AUTOSAR XML (schema 00046)
package /ComponentTypes
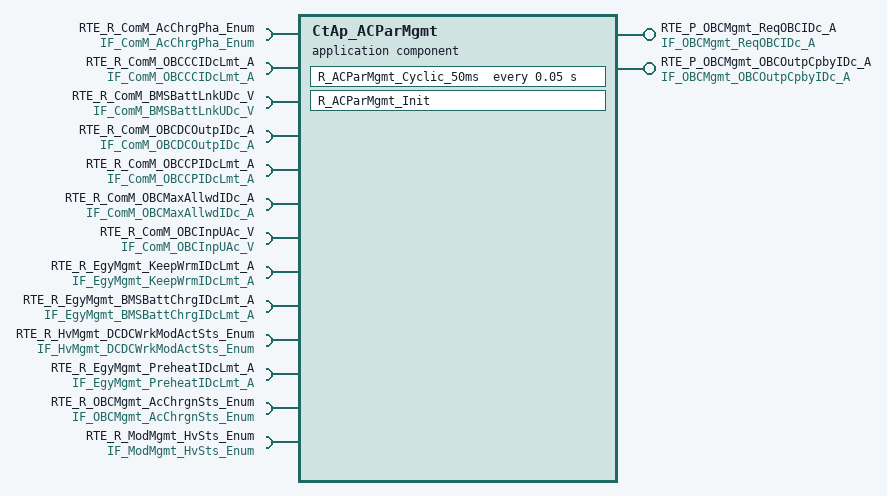
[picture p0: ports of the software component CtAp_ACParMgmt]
  application sw component type CtAp_ACParMgmt
    provide port RTE_P_OBCMgmt_ReqOBCIDc_A: nonqueued-sender-com-spec{data-element=tec_OBCMgmt_ReqOBCIDc_A, init-value=0}, provided-interface=IF_OBCMgmt_ReqOBCIDc_A
    provide port RTE_P_OBCMgmt_OBCOutpCpbyIDc_A: nonqueued-sender-com-spec{data-element=tec_OBCMgmt_OBCOutpCpbyIDc_A, init-value=0}, provided-interface=IF_OBCMgmt_OBCOutpCpbyIDc_A
    13 x require port:
      RTE_R_ComM_AcChrgPha_Enum: nonqueued-receiver-com-spec{data-element=tec_ComM_AcChrgPha_Enum, filter=data-filter-type=ALWAYS, init-value=0}, required-interface=IF_ComM_AcChrgPha_Enum
      RTE_R_ComM_OBCCCIDcLmt_A: nonqueued-receiver-com-spec{data-element=tec_ComM_OBCCCIDcLmt_A, filter=data-filter-type=ALWAYS, init-value=0}, required-interface=IF_ComM_OBCCCIDcLmt_A
      RTE_R_ComM_BMSBattLnkUDc_V: nonqueued-receiver-com-spec{data-element=tec_ComM_BMSBattLnkUDc_V, filter=data-filter-type=ALWAYS, init-value=0}, required-interface=IF_ComM_BMSBattLnkUDc_V
      RTE_R_ComM_OBCDCOutpIDc_A: nonqueued-receiver-com-spec{data-element=tec_ComM_OBCDCOutpIDc_A, filter=data-filter-type=ALWAYS, init-value=0}, required-interface=IF_ComM_OBCDCOutpIDc_A
      RTE_R_ComM_OBCCPIDcLmt_A: nonqueued-receiver-com-spec{data-element=tec_ComM_OBCCPIDcLmt_A, filter=data-filter-type=ALWAYS, init-value=0}, required-interface=IF_ComM_OBCCPIDcLmt_A
      RTE_R_ComM_OBCMaxAllwdIDc_A: nonqueued-receiver-com-spec{data-element=tec_ComM_OBCMaxAllwdIDc_A, filter=data-filter-type=ALWAYS, init-value=0}, required-interface=IF_ComM_OBCMaxAllwdIDc_A
      RTE_R_ComM_OBCInpUAc_V: nonqueued-receiver-com-spec{data-element=tec_ComM_OBCInpUAc_V, filter=data-filter-type=ALWAYS, init-value=0}, required-interface=IF_ComM_OBCInpUAc_V
      RTE_R_EgyMgmt_KeepWrmIDcLmt_A: nonqueued-receiver-com-spec{data-element=tec_EgyMgmt_KeepWrmIDcLmt_A, filter=data-filter-type=ALWAYS, init-value=0}, required-interface=IF_EgyMgmt_KeepWrmIDcLmt_A
      RTE_R_EgyMgmt_BMSBattChrgIDcLmt_A: nonqueued-receiver-com-spec{data-element=tec_EgyMgmt_BMSBattChrgIDcLmt_A, filter=data-filter-type=ALWAYS, init-value=0}, required-interface=IF_EgyMgmt_BMSBattChrgIDcLmt_A
      RTE_R_HvMgmt_DCDCWrkModActSts_Enum: nonqueued-receiver-com-spec{data-element=tec_HvMgmt_DCDCWrkModActSts_Enum, filter=data-filter-type=ALWAYS, init-value=0}, required-interface=IF_HvMgmt_DCDCWrkModActSts_Enum
      RTE_R_EgyMgmt_PreheatIDcLmt_A: nonqueued-receiver-com-spec{data-element=tec_EgyMgmt_PreheatIDcLmt_A, filter=data-filter-type=ALWAYS, init-value=0}, required-interface=IF_EgyMgmt_PreheatIDcLmt_A
      RTE_R_OBCMgmt_AcChrgnSts_Enum: nonqueued-receiver-com-spec{data-element=tec_OBCMgmt_AcChrgnSts_Enum, filter=data-filter-type=ALWAYS, init-value=0}, required-interface=IF_OBCMgmt_AcChrgnSts_Enum
      RTE_R_ModMgmt_HvSts_Enum: nonqueued-receiver-com-spec{data-element=tec_ModMgmt_HvSts_Enum, filter=data-filter-type=ALWAYS, init-value=0}, required-interface=IF_ModMgmt_HvSts_Enum
    behavior CtAp_ACParMgmt_InternalBehavior
      timing event TMT_R_ACParMgmt_Cyclic_50ms: start-on-event=R_ACParMgmt_Cyclic_50ms, period=0.05
      init event CtAp_ACParMgmt_InitEvent: start-on-event=R_ACParMgmt_Init
      runnable R_ACParMgmt_Cyclic_50ms
        data-receive-point-by-arguments:
          13 x access:
            REC_RTE_R_ComM_AcChrgPha_Enum_tec_ComM_AcChrgPha_Enum: accessed-variable=RTE_R_ComM_AcChrgPha_Enum.tec_ComM_AcChrgPha_Enum
            REC_RTE_R_ComM_BMSBattLnkUDc_V_tec_ComM_BMSBattLnkUDc_V: accessed-variable=RTE_R_ComM_BMSBattLnkUDc_V.tec_ComM_BMSBattLnkUDc_V
            REC_RTE_R_ComM_OBCCCIDcLmt_A_tec_ComM_OBCCCIDcLmt_A: accessed-variable=RTE_R_ComM_OBCCCIDcLmt_A.tec_ComM_OBCCCIDcLmt_A
            REC_RTE_R_ComM_OBCCPIDcLmt_A_tec_ComM_OBCCPIDcLmt_A: accessed-variable=RTE_R_ComM_OBCCPIDcLmt_A.tec_ComM_OBCCPIDcLmt_A
            REC_RTE_R_ComM_OBCDCOutpIDc_A_tec_ComM_OBCDCOutpIDc_A: accessed-variable=RTE_R_ComM_OBCDCOutpIDc_A.tec_ComM_OBCDCOutpIDc_A
            REC_RTE_R_ComM_OBCInpUAc_V_tec_ComM_OBCInpUAc_V: accessed-variable=RTE_R_ComM_OBCInpUAc_V.tec_ComM_OBCInpUAc_V
            REC_RTE_R_ComM_OBCMaxAllwdIDc_A_tec_ComM_OBCMaxAllwdIDc_A: accessed-variable=RTE_R_ComM_OBCMaxAllwdIDc_A.tec_ComM_OBCMaxAllwdIDc_A
            REC_RTE_R_EgyMgmt_BMSBattChrgIDcLmt_A_tec_EgyMgmt_BMSBattChrgIDcLmt_A: accessed-variable=RTE_R_EgyMgmt_BMSBattChrgIDcLmt_A.tec_EgyMgmt_BMSBattChrgIDcLmt_A
            REC_RTE_R_EgyMgmt_KeepWrmIDcLmt_A_tec_EgyMgmt_KeepWrmIDcLmt_A: accessed-variable=RTE_R_EgyMgmt_KeepWrmIDcLmt_A.tec_EgyMgmt_KeepWrmIDcLmt_A
            REC_RTE_R_EgyMgmt_PreheatIDcLmt_A_tec_EgyMgmt_PreheatIDcLmt_A: accessed-variable=RTE_R_EgyMgmt_PreheatIDcLmt_A.tec_EgyMgmt_PreheatIDcLmt_A
            REC_RTE_R_HvMgmt_DCDCWrkModActSts_Enum_tec_HvMgmt_DCDCWrkModActSts_Enum: accessed-variable=RTE_R_HvMgmt_DCDCWrkModActSts_Enum.tec_HvMgmt_DCDCWrkModActSts_Enum
            REC_RTE_R_ModMgmt_HvSts_Enum_tec_ModMgmt_HvSts_Enum: accessed-variable=RTE_R_ModMgmt_HvSts_Enum.tec_ModMgmt_HvSts_Enum
            REC_RTE_R_OBCMgmt_AcChrgnSts_Enum_tec_OBCMgmt_AcChrgnSts_Enum: accessed-variable=RTE_R_OBCMgmt_AcChrgnSts_Enum.tec_OBCMgmt_AcChrgnSts_Enum
        data-send-points:
          access SEND_RTE_P_OBCMgmt_OBCOutpCpbyIDc_A_tec_OBCMgmt_OBCOutpCpbyIDc_A: accessed-variable=RTE_P_OBCMgmt_OBCOutpCpbyIDc_A.tec_OBCMgmt_OBCOutpCpbyIDc_A
          access SEND_RTE_P_OBCMgmt_ReqOBCIDc_A_tec_OBCMgmt_ReqOBCIDc_A: accessed-variable=RTE_P_OBCMgmt_ReqOBCIDc_A.tec_OBCMgmt_ReqOBCIDc_A
      runnable R_ACParMgmt_Init
  swc implementation CtAp_ACParMgmt_Implementation: behavior=CtAp_ACParMgmt_InternalBehavior
    code-descriptors:
      code Default: artifact-descriptors=autosar-engineering-object=category=SWOBJ
